# PIC32CX5112MTSH128 register map
Vendor: Microchip Technology; Series: PIC32CXMTSH; File version: 0
CPU: CM4 r0p1, selectable endian, MPU, FPU, 4 interrupt priority bits
Registers are 32-bit, read-write, reset 0x0 unless marked. A register's access mark holds for its fields unless they carry their own. Offsets are from the block's base; [hi:lo] are bit positions; {n}, {i} and the like mark numbered series.

## AESB — Advanced Encryption Standard Bridge
Base 0x44004000; register names take the prefix AESB_
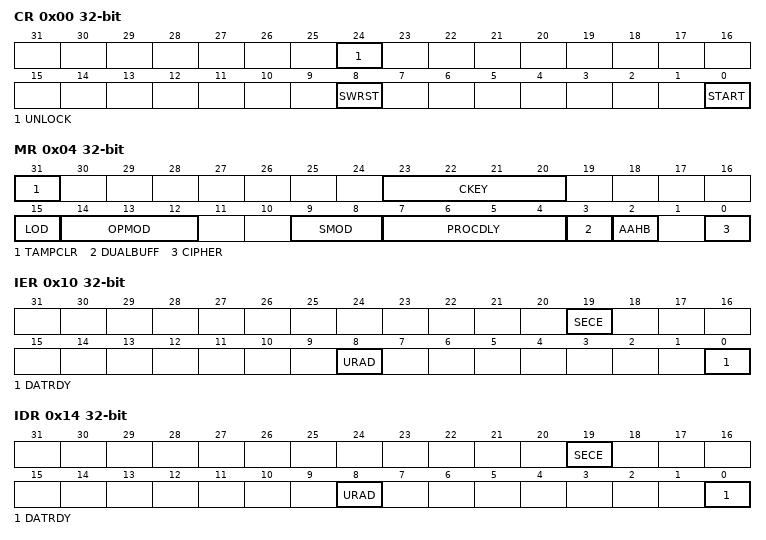
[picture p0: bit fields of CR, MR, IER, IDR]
0x00 CR wo — Control Register
  [24] UNLOCK — Unlock Processing
  [8] SWRST — Software Reset
  [0] START — Start Processing
0x04 MR — Mode Register
  [31] TAMPCLR — Tamper Clear Enable
  [23:20] CKEY — Key
    14=PASSWD (Must be written with 0xE the first time that AESB_MR is programmed. For subsequent programming of AESB_MR, any value can be written, including that of 0xE. Always reads as 0.)
  [15] LOD — Last Output Data Mode
  [14:12] OPMOD — Operating Mode
    0=ECB (Electronic Code Book mode); 1=CBC (Cipher Block Chaining mode); 4=CTR (Counter mode (16-bit internal counter))
  [9:8] SMOD — Start Mode
    0=MANUAL_START (Manual mode); 1=AUTO_START (Auto mode); 2=IDATAR0_START (AESB_IDATAR0 access only Auto mode)
  [7:4] PROCDLY — Processing Delay
  [3] DUALBUFF — Dual Input Buffer
    0=INACTIVE (AESB_IDATARx cannot be written during processing of previous block.); 1=ACTIVE (AESB_IDATARx can be written during processing of previous block when SMOD = 0x2. It speeds up the overall runtime of large files.)
  [2] AAHB — Automatic Bridge Mode
  [0] CIPHER — Processing Mode
0x10 IER wo — Interrupt Enable Register
  [19] SECE — Security and/or Safety Event
  [8] URAD — Unspecified Register Access Detection Interrupt Enable
  [0] DATRDY — Data Ready Interrupt Enable
0x14 IDR wo — Interrupt Disable Register
  [19] SECE — Security and/or Safety Event
  [8] URAD — Unspecified Register Access Detection Interrupt Disable
  [0] DATRDY — Data Ready Interrupt Disable
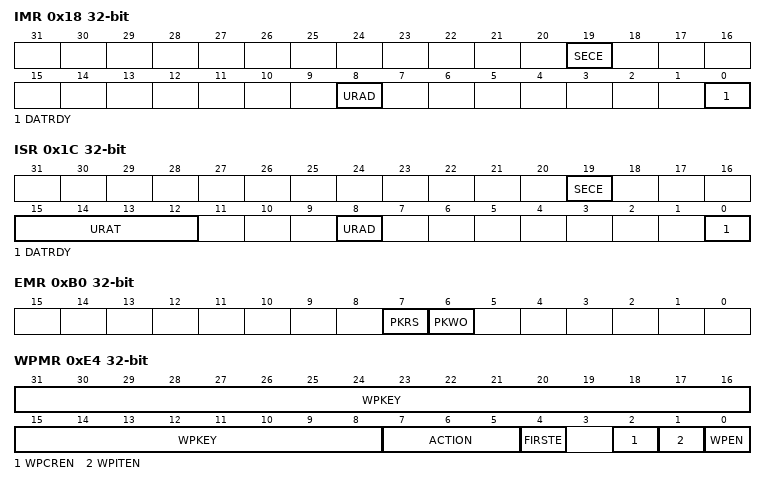
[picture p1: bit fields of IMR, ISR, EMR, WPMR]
0x18 IMR ro — Interrupt Mask Register
  [19] SECE — Security and/or Safety Event
  [8] URAD — Unspecified Register Access Detection Interrupt Mask
  [0] DATRDY — Data Ready Interrupt Mask
0x1C ISR ro — Interrupt Status Register
  [19] SECE — Security and/or Safety Event
  [15:12] URAT — Unspecified Register Access
    0=IDR_WR_PROCESSING (Input Data register written during the data processing when SMOD = 0x2 mode); 1=ODR_RD_PROCESSING (Output Data register read during the data processing); 2=MR_WR_PROCESSING (Mode register written during the data processing); 3=ODR_RD_SUBKGEN (Output Data register read during the sub-keys generation); 4=MR_WR_SUBKGEN (Mode register written during the sub-keys generation); 5=WOR_RD_ACCESS (Write-only register read access)
  [8] URAD — Unspecified Register Access Detection Status
  [0] DATRDY — Data Ready
{0x20+4i} KEYWR[{i}] (i=0..3) wo — Key Word Register
  [31:0] KEYW — Key Word
{0x40+4i} IDATAR[{i}] (i=0..3) wo — Input Data Register
  [31:0] IDATA — Input Data Word
{0x50+4i} ODATAR[{i}] (i=0..3) ro — Output Data Register
  [31:0] ODATA — Output Data
{0x60+4i} IVR[{i}] (i=0..3) wo — Initialization Vector Register
  [31:0] IV — Initialization Vector
0xB0 EMR — Extended Mode Register
  [7] PKRS — Private Key Internal Register Select
  [6] PKWO — Private Key Write Once
0xE4 WPMR — Write Protection Mode Register
  [31:8] WPKEY — Write Protection Key
    0x414553=PASSWD (Writing any other value in this field aborts the write operation of the WPEN,WPITEN,WPCREN bits. Always reads as 0.)
  [7:5] ACTION — Action on Abnormal Event Detection
    0=REPORT_ONLY (No action (stop or clear key) is performed when one of PKRPVS, WPVS, CGD, SEQE, or SWE flags is set.); 1=LOCK_PKRPVS_WPVS_SWE (If a processing is in progress when the AESB_WPSR.PKRPVS/WPVS/SWE event detection occurs, the current processing is ended normally but no other processing is started while a AESB_CR.UNLOCK command is issued.); 2=LOCK_CGD_SEQE (If a processing is in progress when the AESB_WPSR.CGD/SEQE event detection occurs, the current processing is ended normally but no other processing is started while a AESB_CR.UNLOCK command is issued.); 3=LOCK_ANY_EV (If a processing is in progress when the AESB_WPSR.PKRPVS/WPVS/CGD/SEQE/SWE events detection occurs, the current processing is ended normally but no other processing is started while a AESB_CR.UNLOCK command is issued.); 4=CLEAR_PKRPVS_WPVS_SWE (If a processing is in progress when the AESB_WPSR.PKRPVS/WPVS/SWE events detection occurs, the current processing is ended normally but no other processing is started while a AESB_CR.UNLOCK command is issued. Moreover, the AESB_KEYWRx key is immediately cleared.); 5=CLEAR_CGD_SEQE (If a processing is in progress when the AESB_WPSR.CGD/SEQE events detection occurs, the current processing is ended normally but no other processing is started while a AESB_CR.UNLOCK command is issued. Moreover, the AESB_KEYWRx key is immediately cleared.); 6=CLEAR_ANY_EV (If a processing is in progress when the AESB_WPSR.PKRPVS/WPVS/CGD/SEQE/SWE events detection occurs, the current processing is ended normally but no other processing is started while a AESB_CR.UNLOCK command is issued. Moreover, the AESB_KEYWRx key is immediately cleared.)
  [4] FIRSTE — First Error Report Enable
  [2] WPCREN — Write Protection Control Enable
  [1] WPITEN — Write Protection Interruption Enable
  [0] WPEN — Write Protection Configuration Enable
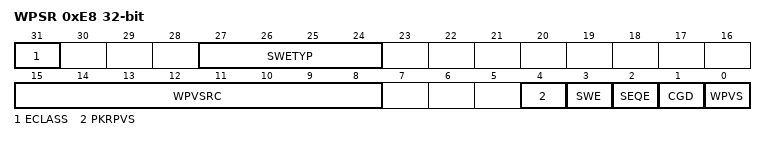
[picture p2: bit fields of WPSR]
0xE8 WPSR ro — Write Protection Status Register
  [31] ECLASS — Software Error Class (cleared on read)
    0=WARNING (An abnormal access that does not affect system functionality); 1=ERROR (An access is performed into key, input data, control registers while the AESB is performing an encryption/decryption or a start is request by software or DMA while the key is not fully configured.)
  [27:24] SWETYP — Software Error Type (cleared on read)
    0=READ_WO (A write-only register has been read (Warning).); 1=WRITE_RO (AESB is enabled and a write access has been performed on a read-only register (Warning).); 2=UNDEF_RW (Access to an undefined address (Warning).); 3=CTRL_START (Abnormal use of AESB_CR.START command when DMA access is configured.); 4=WEIRD_ACTION (A Private Key Bus access, key write, init value write, output data read or AESB_MR and AESB_EMR write has been performed while a process is in progress (abnormal).); 5=INCOMPLETE_KEY (A tentative of start is required while the key is not fully loaded into the AESB_KEYWRx registers.)
  [15:8] WPVSRC — Write Protection Violation Source
  [4] PKRPVS — Private Key Internal Register Protection Violation Status (cleared on read)
  [3] SWE — Software Control Error (cleared on read)
  [2] SEQE — Internal Sequencer Error (cleared on read)
  [1] CGD — Clock Glitch Detected (cleared on read)
  [0] WPVS — Write Protection Violation Status (cleared on read)

## Notices in the file
Copyright (c) 2017 Microchip Technology Inc.
SPDX-License-Identifier: Apache-2.0
Licensed under the Apache License, Version 2.0 (the "License");
you may not use this file except in compliance with the License.
You may obtain a copy of the License at
http://www.apache.org/licenses/LICENSE-2.0
Unless required by applicable law or agreed to in writing, software
distributed under the License is distributed on an "AS IS" BASIS,
WITHOUT WARRANTIES OR CONDITIONS OF ANY KIND, either express or implied.
See the License for the specific language governing permissions and
limitations under the License.
